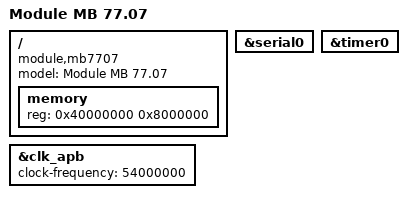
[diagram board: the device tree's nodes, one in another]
/dts-v1/;

#include "k1879hb1ya.dtsi"

/ {
	model = "Module MB 77.07";
	compatible = "module,mb7707";

	memory {
		reg = <0x40000000 0x8000000>;
	};
};

&clk_apb {
	clock-frequency = <54000000>;
};

&serial0 {
	status = "okay";
};

&timer0 {
	status = "okay";
};
